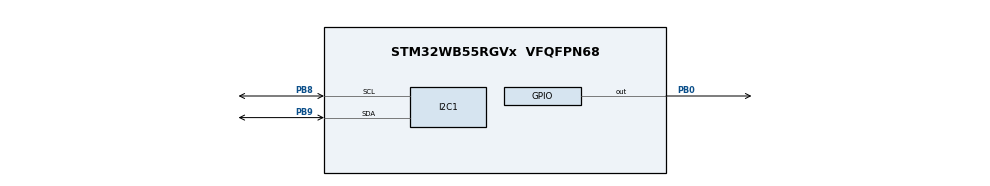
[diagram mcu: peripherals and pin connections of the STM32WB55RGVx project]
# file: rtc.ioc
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I2C1.Timing=0x00100D14
Mcu.Family=STM32WB
Mcu.Name=STM32WB55RGVx
Mcu.Package=VFQFPN68
NVIC.PriorityGroup=NVIC_PRIORITYGROUP_4
NVIC.RTC_Alarm_IRQn=true\:0\:0\:false\:false\:true\:true\:true\:true
PB0.Signal=GPIO_Output
PB8.Mode=I2C
PB8.Signal=I2C1_SCL
PB9.Mode=I2C
PB9.Signal=I2C1_SDA
PC14-OSC32_IN.Mode=LSE-External-Oscillator
PC14-OSC32_IN.Signal=RCC_OSC32_IN
PC15-OSC32_OUT.Mode=LSE-External-Oscillator
PC15-OSC32_OUT.Signal=RCC_OSC32_OUT
ProjectManager.HeapSize=0x200
ProjectManager.StackSize=0x400
ProjectManager.TargetToolchain=STM32CubeIDE
RCC.ADCFreq_Value=16000000
RCC.AHBFreq_Value=4000000
RCC.APB1Freq_Value=4000000
RCC.APB1TimFreq_Value=4000000
RCC.APB2Freq_Value=4000000
RCC.APB2TimFreq_Value=4000000
RCC.APB3Freq_Value=16000000
RCC.CortexFreq_Value=4000000
RCC.HCLKFreq_Value=4000000
RCC.HSE_VALUE=8000000
RCC.HSI48_VALUE=48000000
RCC.HSI_VALUE=16000000
RCC.RTCClockSelection=RCC_RTCCLKSOURCE_LSE
RCC.SYSCLKFreq_VALUE=4000000
RCC.USBFreq_Value=16000000
RCC.VCOOutputFreq_Value=32000000
RTC.Alarm-Alarm\ A=RTC_ALARM_A
RTC.AlarmDateWeekDay-Alarm\ A=17
RTC.AlarmMaskDateWeekDay-Alarm\ A=RTC_ALARMMASK_DATEWEEKDAY
RTC.AlarmMaskHours-Alarm\ A=RTC_ALARMMASK_HOURS
RTC.AlarmMaskMinutes-Alarm\ A=RTC_ALARMMASK_MINUTES
RTC.AlarmMaskSeconds-Alarm\ A=RTC_ALARMMASK_SECONDS
RTC.Date=17
RTC.Format=RTC_FORMAT_BIN
RTC.Hours=2
RTC.Hours_A-Alarm\ A=3
RTC.Minutes=30
RTC.Minutes_A-Alarm\ A=8
RTC.Month=RTC_MONTH_MAY
RTC.WeekDay=RTC_WEEKDAY_SUNDAY
RTC.Year=25
VP_MEMORYMAP_VS_MEMORYMAP.Mode=CurAppReg
VP_RTC_VS_RTC_Activate.Mode=RTC_Enabled
VP_RTC_VS_RTC_Alarm_A_Intern.Mode=Alarm A
VP_RTC_VS_RTC_Calendar.Mode=RTC_Calendar
board=custom

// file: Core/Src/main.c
/* USER CODE BEGIN Header */
/**
  ******************************************************************************
  * @file           : main.c
  * @brief          : Main program body
  ******************************************************************************
  * @attention
  *
  * Copyright (c) 2025 STMicroelectronics.
  * All rights reserved.
  *
  * This software is licensed under terms that can be found in the LICENSE file
  * in the root directory of this software component.
  * If no LICENSE file comes with this software, it is provided AS-IS.
  *
  ******************************************************************************
  */
/* USER CODE END Header */
#include "main.h"
#include <stdio.h>
#include <string.h>

/* USER CODE BEGIN PTD */
RTC_TimeTypeDef now;
RTC_DateTypeDef today;

/* USER CODE END PTD */

I2C_HandleTypeDef hi2c1;

RTC_HandleTypeDef hrtc;

void SystemClock_Config(void);
void PeriphCommonClock_Config(void);
static void MX_GPIO_Init(void);
static void MX_I2C1_Init(void);
static void MX_RTC_Init(void);

/* USER CODE BEGIN 0 */

//
//void HAL_RTC_AlarmAEventCallback(RTC_HandleTypeDef *hrtc)
//{
//  RTC_AlarmTypeDef sAlarm;
//
//
//  HAL_RTC_GetAlarm(hrtc,&sAlarm,RTC_ALARM_A,FORMAT_BIN);
//
//  if(sAlarm.AlarmTime.Seconds>58)
//  {
//    sAlarm.AlarmTime.Seconds=0;
//
//  }
//  else
//  {
//    sAlarm.AlarmTime.Seconds=sAlarm.AlarmTime.Seconds+1;
//  }
//    while(HAL_RTC_SetAlarm_IT(hrtc, &sAlarm, FORMAT_BIN)!=HAL_OK){}
//
//    HAL_GPIO_TogglePin(GPIOB, GPIO_PIN_0);
//}
/*
 * It retrieves the current alarm settings using HAL_RTC_GetAlarm()
 *
It increments the alarm's seconds value by 1, resetting to 0 if it exceeds 58

It sets the new alarm time with the incremented seconds value using HAL_RTC_SetAlarm_IT()

It toggles the state of pin 0 on GPIO port B

Essentially, this function creates a repeating alarm that triggers every second. Each time the alarm triggers, it:

Updates the alarm to fire again after one more second
Toggles a GPIO pin (likely connected to an LED or other indicator)
 */

/* USER CODE END 0 */

int main(void)
{

  /* MCU Configuration--------------------------------------------------------*/

  /* Reset of all peripherals, Initializes the Flash interface and the Systick. */
  HAL_Init();

  /* Configure the system clock */
  SystemClock_Config();

  /* Configure the peripherals common clocks */
  PeriphCommonClock_Config();

  /* Initialize all configured peripherals */
  MX_GPIO_Init();
  MX_I2C1_Init();
  MX_RTC_Init();

  /* Infinite loop */
  while (1)
  {
	  HAL_RTC_GetTime(&hrtc, &now, RTC_FORMAT_BIN);
	  HAL_RTC_GetDate(&hrtc, &today, RTC_FORMAT_BIN);
	  HAL_Delay(1000);  // Update every second
  }
}

void SystemClock_Config(void)
{
  RCC_OscInitTypeDef RCC_OscInitStruct = {0};
  RCC_ClkInitTypeDef RCC_ClkInitStruct = {0};

  /** Configure LSE Drive Capability
  */
  HAL_PWR_EnableBkUpAccess();
  __HAL_RCC_LSEDRIVE_CONFIG(RCC_LSEDRIVE_MEDIUMHIGH);

  /** Configure the main internal regulator output voltage
  */
  __HAL_PWR_VOLTAGESCALING_CONFIG(PWR_REGULATOR_VOLTAGE_SCALE1);

  /** Initializes the RCC Oscillators according to the specified parameters
  * in the RCC_OscInitTypeDef structure.
  */
  RCC_OscInitStruct.OscillatorType = RCC_OSCILLATORTYPE_HSI|RCC_OSCILLATORTYPE_LSE
                              |RCC_OSCILLATORTYPE_MSI;
  RCC_OscInitStruct.LSEState = RCC_LSE_ON;
  RCC_OscInitStruct.HSIState = RCC_HSI_ON;
  RCC_OscInitStruct.MSIState = RCC_MSI_ON;
  RCC_OscInitStruct.HSICalibrationValue = RCC_HSICALIBRATION_DEFAULT;
  RCC_OscInitStruct.MSICalibrationValue = RCC_MSICALIBRATION_DEFAULT;
  RCC_OscInitStruct.MSIClockRange = RCC_MSIRANGE_6;
  RCC_OscInitStruct.PLL.PLLState = RCC_PLL_NONE;
  if (HAL_RCC_OscConfig(&RCC_OscInitStruct) != HAL_OK)
  {
    Error_Handler();
  }

  /** Configure the SYSCLKSource, HCLK, PCLK1 and PCLK2 clocks dividers
  */
  RCC_ClkInitStruct.ClockType = RCC_CLOCKTYPE_HCLK4|RCC_CLOCKTYPE_HCLK2
                              |RCC_CLOCKTYPE_HCLK|RCC_CLOCKTYPE_SYSCLK
                              |RCC_CLOCKTYPE_PCLK1|RCC_CLOCKTYPE_PCLK2;
  RCC_ClkInitStruct.SYSCLKSource = RCC_SYSCLKSOURCE_MSI;
  RCC_ClkInitStruct.AHBCLKDivider = RCC_SYSCLK_DIV1;
  RCC_ClkInitStruct.APB1CLKDivider = RCC_HCLK_DIV1;
  RCC_ClkInitStruct.APB2CLKDivider = RCC_HCLK_DIV1;
  RCC_ClkInitStruct.AHBCLK2Divider = RCC_SYSCLK_DIV1;
  RCC_ClkInitStruct.AHBCLK4Divider = RCC_SYSCLK_DIV1;

  if (HAL_RCC_ClockConfig(&RCC_ClkInitStruct, FLASH_LATENCY_0) != HAL_OK)
  {
    Error_Handler();
  }
}

void PeriphCommonClock_Config(void)
{
  RCC_PeriphCLKInitTypeDef PeriphClkInitStruct = {0};

  /** Initializes the peripherals clock
  */
  PeriphClkInitStruct.PeriphClockSelection = RCC_PERIPHCLK_SMPS;
  PeriphClkInitStruct.SmpsClockSelection = RCC_SMPSCLKSOURCE_HSI;
  PeriphClkInitStruct.SmpsDivSelection = RCC_SMPSCLKDIV_RANGE1;

  if (HAL_RCCEx_PeriphCLKConfig(&PeriphClkInitStruct) != HAL_OK)
  {
    Error_Handler();
  }
}

static void MX_I2C1_Init(void)
{

  hi2c1.Instance = I2C1;
  hi2c1.Init.Timing = 0x00100D14;
  hi2c1.Init.OwnAddress1 = 0;
  hi2c1.Init.AddressingMode = I2C_ADDRESSINGMODE_7BIT;
  hi2c1.Init.DualAddressMode = I2C_DUALADDRESS_DISABLE;
  hi2c1.Init.OwnAddress2 = 0;
  hi2c1.Init.OwnAddress2Masks = I2C_OA2_NOMASK;
  hi2c1.Init.GeneralCallMode = I2C_GENERALCALL_DISABLE;
  hi2c1.Init.NoStretchMode = I2C_NOSTRETCH_DISABLE;
  if (HAL_I2C_Init(&hi2c1) != HAL_OK)
  {
    Error_Handler();
  }

  /** Configure Analogue filter
  */
  if (HAL_I2CEx_ConfigAnalogFilter(&hi2c1, I2C_ANALOGFILTER_ENABLE) != HAL_OK)
  {
    Error_Handler();
  }

  /** Configure Digital filter
  */
  if (HAL_I2CEx_ConfigDigitalFilter(&hi2c1, 0) != HAL_OK)
  {
    Error_Handler();
  }

}

static void MX_RTC_Init(void)
{

  RTC_TimeTypeDef sTime = {0};
  RTC_DateTypeDef sDate = {0};
  RTC_AlarmTypeDef sAlarm = {0};

  /** Initialize RTC Only
  */
  hrtc.Instance = RTC;
  hrtc.Init.HourFormat = RTC_HOURFORMAT_24;
  hrtc.Init.AsynchPrediv = 127;
  hrtc.Init.SynchPrediv = 255;
  hrtc.Init.OutPut = RTC_OUTPUT_DISABLE;
  hrtc.Init.OutPutPolarity = RTC_OUTPUT_POLARITY_HIGH;
  hrtc.Init.OutPutType = RTC_OUTPUT_TYPE_OPENDRAIN;
  hrtc.Init.OutPutRemap = RTC_OUTPUT_REMAP_NONE;
  if (HAL_RTC_Init(&hrtc) != HAL_OK)
  {
    Error_Handler();
  }

  /** Initialize RTC and set the Time and Date
  */
  sTime.Hours = 2;
  sTime.Minutes = 30;
  sTime.Seconds = 0;
  sTime.SubSeconds = 0x0;
  sTime.DayLightSaving = RTC_DAYLIGHTSAVING_NONE;
  sTime.StoreOperation = RTC_STOREOPERATION_RESET;
  if (HAL_RTC_SetTime(&hrtc, &sTime, RTC_FORMAT_BIN) != HAL_OK)
  {
    Error_Handler();
  }
  sDate.WeekDay = RTC_WEEKDAY_SUNDAY;
  sDate.Month = RTC_MONTH_MAY;
  sDate.Date = 17;
  sDate.Year = 25;
  if (HAL_RTC_SetDate(&hrtc, &sDate, RTC_FORMAT_BIN) != HAL_OK)
  {
    Error_Handler();
  }

  /** Enable the Alarm A
  */
  sAlarm.AlarmTime.Hours = 3;
  sAlarm.AlarmTime.Minutes = 8;
  sAlarm.AlarmTime.Seconds = 0;
  sAlarm.AlarmTime.SubSeconds = 0;
  sAlarm.AlarmTime.DayLightSaving = RTC_DAYLIGHTSAVING_NONE;
  sAlarm.AlarmTime.StoreOperation = RTC_STOREOPERATION_RESET;
  sAlarm.AlarmMask = RTC_ALARMMASK_ALL;
  sAlarm.AlarmSubSecondMask = RTC_ALARMSUBSECONDMASK_ALL;
  sAlarm.AlarmDateWeekDaySel = RTC_ALARMDATEWEEKDAYSEL_DATE;
  sAlarm.AlarmDateWeekDay = 17;
  sAlarm.Alarm = RTC_ALARM_A;
  if (HAL_RTC_SetAlarm_IT(&hrtc, &sAlarm, RTC_FORMAT_BIN) != HAL_OK)
  {
    Error_Handler();
  }

}

static void MX_GPIO_Init(void)
{
  GPIO_InitTypeDef GPIO_InitStruct = {0};

  /* GPIO Ports Clock Enable */
  __HAL_RCC_GPIOC_CLK_ENABLE();
  __HAL_RCC_GPIOB_CLK_ENABLE();

  /*Configure GPIO pin Output Level */
  HAL_GPIO_WritePin(GPIOB, GPIO_PIN_0, GPIO_PIN_RESET);

  /*Configure GPIO pin : PB0 */
  GPIO_InitStruct.Pin = GPIO_PIN_0;
  GPIO_InitStruct.Mode = GPIO_MODE_OUTPUT_PP;
  GPIO_InitStruct.Pull = GPIO_NOPULL;
  GPIO_InitStruct.Speed = GPIO_SPEED_FREQ_LOW;
  HAL_GPIO_Init(GPIOB, &GPIO_InitStruct);

}

void Error_Handler(void)
{
  __disable_irq();
  while (1)
  {
  }
}
